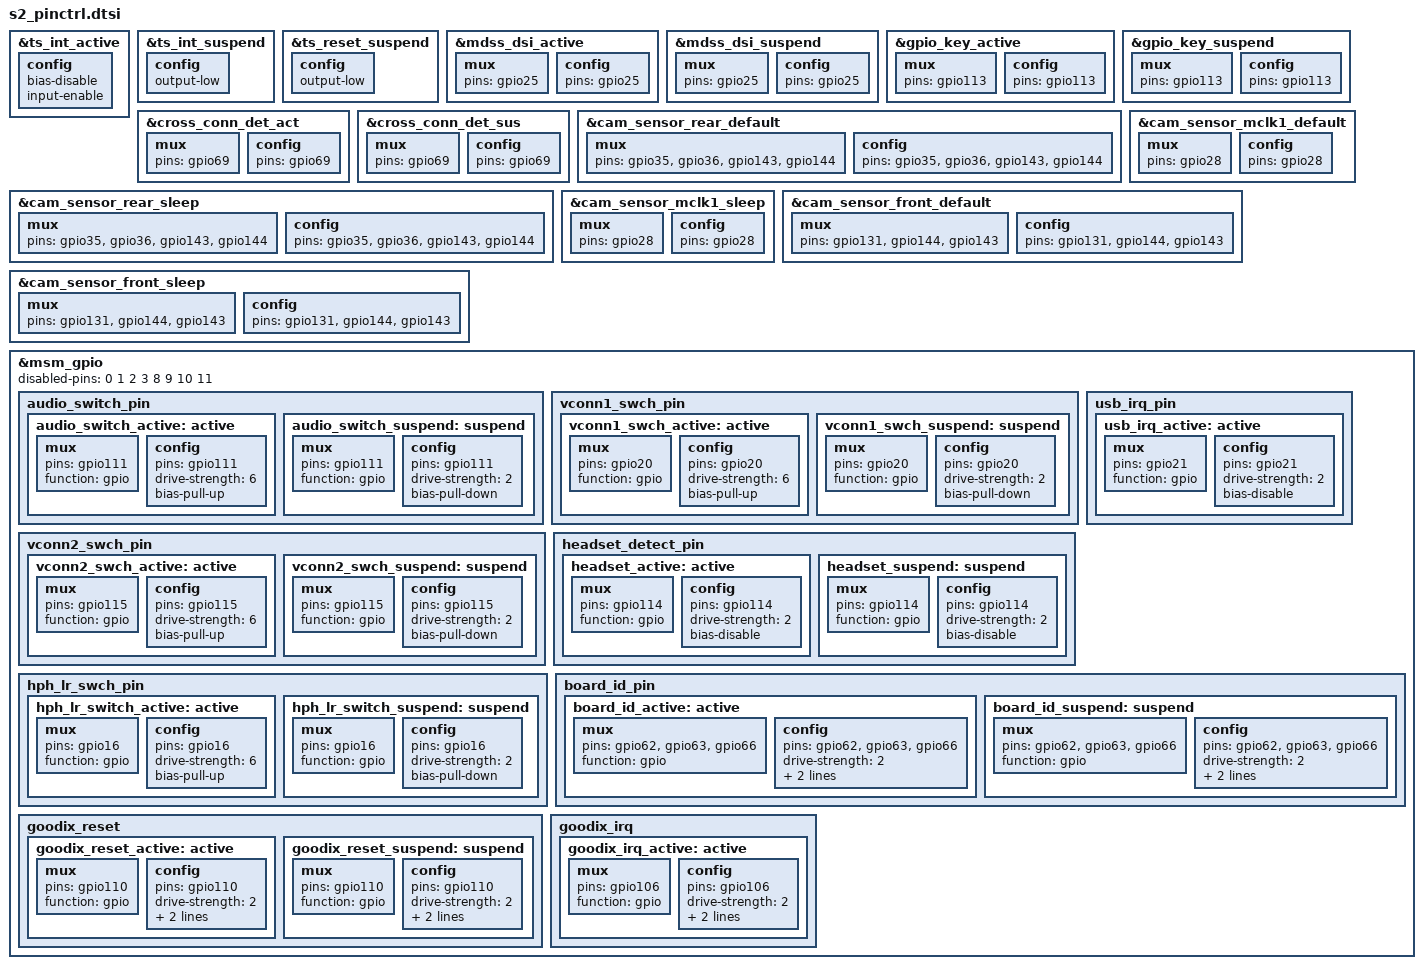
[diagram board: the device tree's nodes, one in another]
/*  Date            Author    	          Why              jira
*/

&ts_int_active {
config {
 /delete-property/  bias-pull-up;
bias-disable;
input-enable;
};
};
&ts_int_suspend {
config {
output-low;
 /delete-property/  bias-pull-down;
};
};

&ts_reset_suspend {
config {
 /delete-property/  bias-pull-down;
output-low;
};
};



&mdss_dsi_active {
mux {
	pins = "gpio25";
};

config {
	pins = "gpio25";
	};
};
&mdss_dsi_suspend {
mux {
	pins = "gpio25";
};

config {
	pins = "gpio25";
	};
};

&gpio_key_active {
mux {
	pins = "gpio113";
};

config {
	pins = "gpio113";
	};
};

&gpio_key_suspend {
mux {
	pins = "gpio113";
};

config {
	pins = "gpio113";
	};
};

&cross_conn_det_act {
mux {
	pins = "gpio69";
};

config {
	pins = "gpio69";
	/delete-property/ output-low;
	};
};

&cross_conn_det_sus {
mux {
	pins = "gpio69";
};

config {
	pins = "gpio69";
	};
};
  
&cam_sensor_rear_default {
	mux {
		pins = "gpio35", "gpio36", "gpio143", "gpio144";
	};

	config {
		pins = "gpio35", "gpio36", "gpio143", "gpio144";
	};
};

&cam_sensor_rear_sleep {
	mux {
		pins = "gpio35", "gpio36", "gpio143", "gpio144";
	};

	config {
		pins = "gpio35", "gpio36", "gpio143", "gpio144";
	};
};

&cam_sensor_mclk1_default {
	mux {
		pins = "gpio28";
	};

	config {
		pins = "gpio28";
	};
};
&cam_sensor_mclk1_sleep {
	mux {
		pins = "gpio28";
	};

	config {
		pins = "gpio28";
	};
};

&cam_sensor_front_default {
	mux {
		pins = "gpio131", "gpio144", "gpio143";
	};

	config {
		pins = "gpio131", "gpio144", "gpio143";
	};
};
&cam_sensor_front_sleep {
	mux {
		pins = "gpio131", "gpio144", "gpio143";
	};

	config {
		pins = "gpio131", "gpio144", "gpio143";
	};
};


&msm_gpio {

disabled-pins = <0 1 2 3 8 9 10 11>;


/*
/delete-node/  cam_sensor_front_vdig;
/delete-node/   cam_sensor_front_vdig_sleep;
/delete-node/ cdc_reset_ctrl;
*/

/delete-node/ pmx_sdc3_clk;
/delete-node/ pmx_sdc3_cmd;
/delete-node/ pmx_sdc3_dat;
 /delete-node/ sdc3_wlan_gpio;
 /delete-node/  cam_sensor_rear_vana;
/delete-node/  cam_sensor_rear_vana_sleep;

/delete-node/   cam_sensor_mclk2_default;
/delete-node/  cam_sensor_mclk2_sleep;
/delete-node/  cam_sensor_front1_default;
/delete-node/  cam_sensor_front1_sleep;
/delete-node/  pmx_rd_nfc_int;
 /delete-node/ pmx_nfc_reset;
 
audio_switch_pin {	
	audio_switch_active: active {
	
		mux {
			pins = "gpio111";
			function = "gpio";
		};

		config {
			pins = "gpio111";
			drive-strength = <6>;
                        bias-pull-up;
		};
	};
	
	audio_switch_suspend: suspend {
		
		mux {
			pins = "gpio111";
			function = "gpio";
		};

		config {
			pins = "gpio111";
			drive-strength = <2>;
                        bias-pull-down;
		};
	};
};

vconn1_swch_pin {	
	vconn1_swch_active: active {
	
		mux {
			pins = "gpio20";
			function = "gpio";
		};

		config {
			pins = "gpio20";
			drive-strength = <6>;
                        bias-pull-up;
		};
	};
	
	vconn1_swch_suspend: suspend {
		
		mux {
			pins = "gpio20";
			function = "gpio";
		};

		config {
			pins = "gpio20";
			drive-strength = <2>;
                        bias-pull-down;
		};
	};
};

vconn2_swch_pin {	
	vconn2_swch_active: active {
	
		mux {
			pins = "gpio115";
			function = "gpio";
		};

		config {
			pins = "gpio115";
			drive-strength = <6>;
                        bias-pull-up;
		};
	};
	
	vconn2_swch_suspend: suspend {
		
		mux {
			pins = "gpio115";
			function = "gpio";
		};

		config {
			pins = "gpio115";
			drive-strength = <2>;
                        bias-pull-down;
		};
	};
};




headset_detect_pin {	
	headset_active: active {
	
		mux {
			pins = "gpio114";
			function = "gpio";
		};

		config {
			pins = "gpio114";
			drive-strength = <2>;
                        bias-disable;
		};
	};
	
	headset_suspend: suspend {
		
		mux {
			pins = "gpio114";
			function = "gpio";
		};

		config {
			pins = "gpio114";
			drive-strength = <2>;
                        bias-disable;
		};
	};
};


hph_lr_swch_pin {	
	hph_lr_switch_active: active {
	
		mux {
			pins = "gpio16";
			function = "gpio";
		};

		config {
			pins = "gpio16";
			drive-strength = <6>;
                        bias-pull-up;
		};
	};
	
	hph_lr_switch_suspend: suspend {
		
		mux {
			pins = "gpio16";
			function = "gpio";
		};

		config {
			pins = "gpio16";
			drive-strength = <2>;
                        bias-pull-down;
		};
	};
};

usb_irq_pin {	
	usb_irq_active: active {
	
		mux {
			pins = "gpio21";
			function = "gpio";
		};

		config {
			pins = "gpio21";
			drive-strength = <2>;
                        bias-disable;
		};
	};
};

                
board_id_pin {	
	board_id_active: active {
	
		mux {
			pins = "gpio62", "gpio63", "gpio66";
			function = "gpio";
		};

		config {
			pins = "gpio62", "gpio63", "gpio66";
			drive-strength = <2>;
                        input-enable;
                        bias-pull-up;
		};
	};

	board_id_suspend: suspend {
	
		mux {
			pins = "gpio62", "gpio63", "gpio66";
			function = "gpio";
		};

		config {
			pins = "gpio62", "gpio63", "gpio66";
			drive-strength = <2>;
                        input-enable;
                        bias-pull-down;
		};
	};
};

 goodix_reset {	
	goodix_reset_active: active {
	
		mux {
			pins = "gpio110";
			function = "gpio";
		};

		config {
			pins = "gpio110";
			drive-strength = <2>;
                        bias-disable;
                        output-high;
		};
	};

	goodix_reset_suspend: suspend {
	
		mux {
			pins = "gpio110";
			function = "gpio";
		};

		config {
			pins = "gpio110";
			drive-strength = <2>;
                        bias-disable;
                        output-low;
		};
	};
};
     
     
     
     
goodix_irq {	
	goodix_irq_active: active {
	
		mux {
			pins = "gpio106";
			function = "gpio";
		};

		config {
			pins = "gpio106";
			drive-strength = <2>;
                        bias-disable;
                       input-enable;
		};
	};
};
              
};

